VERSION ""

NS_ :

BS_:

BU_:
VAL_TABLE_ vtBridgeOperation 0 "Freewheeling" 1 "Forward" 2 "Reverse" 3 "Brake" 7 "Not available" ;
VAL_TABLE_ vtDigitalInput 0 "Low" 1 "High" 2 "Error" 3 "Not available" ;
VAL_TABLE_ vtOnOff 0 "Off" 1 "On" 2 "Error" 3 "Not available" ;
VAL_TABLE_ vtOutputDiag 0 "Unknown" 1 "OK" 2 "Open" 3 "Short to VBAT" 4 "Short to GND" 5 "Over-current" 6 "Over temperature" 14 "Error" 15 "Not available" ;
VAL_TABLE_ vtPwmFreq 0 "1 Hz" 1 "2 Hz" 2 "5 Hz" 3 "10 Hz" 4 "20 Hz" 5 "50 Hz" 6 "100 Hz" 7 "200 Hz" 8 "500 Hz" 9 "1 KHz" 10 "2 KHz" 11 "5 KHz" 12 "10 KHz" 13 "20 KHz" 14 "Error" 15 "Not available" ;
VAL_TABLE_ vtUInt16 65024 "Error" 65535 "Not available" ;
VAL_TABLE_ vtUInt32 -16777217 "Error" -1 "Not available" ;
VAL_TABLE_ vtUInt8 254 "Error" 255 "Not available" ;

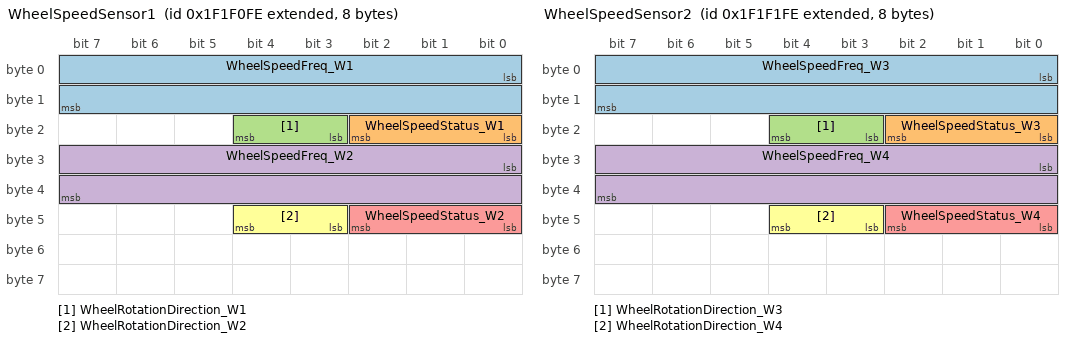
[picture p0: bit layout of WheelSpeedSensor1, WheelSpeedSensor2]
BO_ 2180116734 WheelSpeedSensor1: 8 Vector__XXX
 SG_ WheelSpeedFreq_W1 : 0|16@1+ (0.1,0) [0|6425.5] "Hz" Vector__XXX
 SG_ WheelSpeedStatus_W1 : 16|3@1+ (1,0) [0|7] "" Vector__XXX
 SG_ WheelRotationDirection_W1 : 19|2@1+ (1,0) [0|3] "" Vector__XXX
 SG_ WheelSpeedFreq_W2 : 24|16@1+ (0.1,0) [0|6425.5] "Hz" Vector__XXX
 SG_ WheelSpeedStatus_W2 : 40|3@1+ (1,0) [0|7] "" Vector__XXX
 SG_ WheelRotationDirection_W2 : 43|2@1+ (1,0) [0|3] "" Vector__XXX

BO_ 2180116990 WheelSpeedSensor2: 8 Vector__XXX
 SG_ WheelSpeedFreq_W3 : 0|16@1+ (0.1,0) [0|6425.5] "Hz" Vector__XXX
 SG_ WheelSpeedStatus_W3 : 16|3@1+ (1,0) [0|7] "" Vector__XXX
 SG_ WheelRotationDirection_W3 : 19|2@1+ (1,0) [0|3] "" Vector__XXX
 SG_ WheelSpeedFreq_W4 : 24|16@1+ (0.1,0) [0|6425.5] "Hz" Vector__XXX
 SG_ WheelSpeedStatus_W4 : 40|3@1+ (1,0) [0|7] "" Vector__XXX
 SG_ WheelRotationDirection_W4 : 43|2@1+ (1,0) [0|3] "" Vector__XXX

CM_ "Wheel Speed Sensor messages Version 0.0.1.0
$File: //system_software/components/lib/wheel_speed_sensor/0.36.0.0/dbc/WheelSpeedSensor.dbc $
$Change: 208863 $
$DateTime: 2023/11/10 13:11:00 $
$Revision: #1 $";
CM_ BO_ 2180116734 "Wheel Speed Sensor Iinformation 1";
CM_ SG_ 2180116734 WheelSpeedFreq_W1 "Wheel 1 speed sensor measured frequency";
CM_ SG_ 2180116734 WheelSpeedStatus_W1 "Wheel 1 speed sensor status";
CM_ SG_ 2180116734 WheelRotationDirection_W1 "Wheel 1 rotation direction";
CM_ SG_ 2180116734 WheelSpeedFreq_W2 "Wheel 2 speed sensor measured frequency";
CM_ SG_ 2180116734 WheelSpeedStatus_W2 "Wheel 2 speed sensor status";
CM_ SG_ 2180116734 WheelRotationDirection_W2 "Wheel 2 rotation direction";
CM_ BO_ 2180116990 "Wheel Speed Sensor Iinformation 2";
CM_ SG_ 2180116990 WheelSpeedFreq_W3 "Wheel 3 speed sensor measured frequency";
CM_ SG_ 2180116990 WheelSpeedStatus_W3 "Wheel 3 speed sensor status";
CM_ SG_ 2180116990 WheelRotationDirection_W3 "Wheel 3 rotation direction";
CM_ SG_ 2180116990 WheelSpeedFreq_W4 "Wheel 4 speed sensor measured frequency";
CM_ SG_ 2180116990 WheelSpeedStatus_W4 "Wheel 4 speed sensor status";
CM_ SG_ 2180116990 WheelRotationDirection_W4 "Wheel 4 rotation direction";
BA_DEF_  "BusType" STRING ;
BA_DEF_  "DBName" STRING ;
BA_DEF_  "DatabaseVersion" STRING ;
BA_DEF_ BO_  "GenMsgCycleTime" INT 0 3600000;
BA_DEF_ BO_  "GenMsgILSupport" ENUM  "No","Yes";
BA_DEF_ BO_  "GenMsgRequestable" INT 0 1;
BA_DEF_ BO_  "GenMsgSendType" ENUM  "cyclic","NotUsed","NotUsed","NotUsed","NotUsed","NotUsed","NotUsed","IfActive","noMsgSendType";
BA_DEF_ SG_  "GenSigEVName" STRING ;
BA_DEF_ SG_  "GenSigILSupport" ENUM  "No","Yes";
BA_DEF_ SG_  "GenSigSendType" ENUM  "Cyclic","OnWrite","OnWriteWithRepetition","OnChange","OnChangeWithRepetition","IfActive","IfActiveWithRepetition","NoSigSendType";
BA_DEF_ SG_  "GenSigStartValue" INT 0 2147483647;
BA_DEF_ BU_  "NmStationAddress" INT 0 255;
BA_DEF_  "ProtocolType" STRING ;
BA_DEF_  "SAE_J1939_21_SpecVersion" STRING ;
BA_DEF_  "SAE_J1939_71_SpecVersion" STRING ;
BA_DEF_  "SAE_J1939_73_SpecVersion" STRING ;
BA_DEF_  "SAE_J1939_75_SpecVersion" STRING ;
BA_DEF_  "SAE_J1939_81_SpecVersion" STRING ;
BA_DEF_  "SAE_J1939_DA_SpecVersion" STRING ;
BA_DEF_ SG_  "SigType" ENUM  "Default","Range","RangeSigned","ASCII","Discrete","Control","ReferencePGN","DTC","StringDelimiter","StringLength","StringLengthControl","MessageCounter","MessageChecksum";
BA_DEF_ BO_  "VFrameFormat" ENUM  "StandardCAN","ExtendedCAN","reserved","J1939PG";
BA_DEF_DEF_  "BusType" "";
BA_DEF_DEF_  "DBName" "";
BA_DEF_DEF_  "DatabaseVersion" "";
BA_DEF_DEF_  "GenMsgCycleTime" 0;
BA_DEF_DEF_  "GenMsgILSupport" "Yes";
BA_DEF_DEF_  "GenMsgRequestable" 1;
BA_DEF_DEF_  "GenMsgSendType" "noMsgSendType";
BA_DEF_DEF_  "GenSigEVName" "Env@Nodename_@Signame";
BA_DEF_DEF_  "GenSigILSupport" "Yes";
BA_DEF_DEF_  "GenSigSendType" "NoSigSendType";
BA_DEF_DEF_  "GenSigStartValue" 0;
BA_DEF_DEF_  "NmStationAddress" 254;
BA_DEF_DEF_  "ProtocolType" "";
BA_DEF_DEF_  "SAE_J1939_21_SpecVersion" "";
BA_DEF_DEF_  "SAE_J1939_71_SpecVersion" "";
BA_DEF_DEF_  "SAE_J1939_73_SpecVersion" "";
BA_DEF_DEF_  "SAE_J1939_75_SpecVersion" "";
BA_DEF_DEF_  "SAE_J1939_81_SpecVersion" "";
BA_DEF_DEF_  "SAE_J1939_DA_SpecVersion" "";
BA_DEF_DEF_  "SigType" "Default";
BA_DEF_DEF_  "VFrameFormat" "J1939PG";
BA_ "BusType" "CAN";
BA_ "DBName" "WheelSpeedSensor";
BA_ "DatabaseVersion" "8.5";
BA_ "ProtocolType" "J1939";
BA_ "SAE_J1939_21_SpecVersion" "2006-10";
BA_ "SAE_J1939_71_SpecVersion" "2012-10";
BA_ "SAE_J1939_73_SpecVersion" "2012-10";
BA_ "SAE_J1939_75_SpecVersion" "2012-05";
BA_ "SAE_J1939_81_SpecVersion" "2012-05";
BA_ "SAE_J1939_DA_SpecVersion" "2015-01";
BA_ "GenMsgCycleTime" BO_ 2180116734 10;
BA_ "GenMsgSendType" BO_ 2180116734 0;
BA_ "GenMsgCycleTime" BO_ 2180116990 10;
BA_ "GenMsgSendType" BO_ 2180116990 0;
BA_ "SigType" SG_ 2180116734 WheelSpeedFreq_W1 1;
BA_ "GenSigStartValue" SG_ 2180116734 WheelSpeedStatus_W1 7;
BA_ "GenSigStartValue" SG_ 2180116734 WheelRotationDirection_W1 3;
BA_ "SigType" SG_ 2180116734 WheelSpeedFreq_W2 1;
BA_ "GenSigStartValue" SG_ 2180116734 WheelSpeedStatus_W2 7;
BA_ "GenSigStartValue" SG_ 2180116734 WheelRotationDirection_W2 3;
BA_ "SigType" SG_ 2180116990 WheelSpeedFreq_W3 1;
BA_ "GenSigStartValue" SG_ 2180116990 WheelSpeedStatus_W3 7;
BA_ "GenSigStartValue" SG_ 2180116990 WheelRotationDirection_W3 3;
BA_ "SigType" SG_ 2180116990 WheelSpeedFreq_W4 1;
BA_ "GenSigStartValue" SG_ 2180116990 WheelSpeedStatus_W4 7;
BA_ "GenSigStartValue" SG_ 2180116990 WheelRotationDirection_W4 3;
VAL_ 2180116734 WheelSpeedStatus_W1 0 "OK" 1 "Airgap limit" 2 "Bad airgap" 6 "Error" 7 "Not Available" ;
VAL_ 2180116734 WheelRotationDirection_W1 0 "Right" 1 "Left" 2 "Stop" 3 "Not Available" ;
VAL_ 2180116734 WheelSpeedStatus_W2 0 "OK" 1 "Airgap limit" 2 "Bad airgap" 6 "Error" 7 "Not Available" ;
VAL_ 2180116734 WheelRotationDirection_W2 0 "Right" 1 "Left" 2 "Stop" 3 "Not Available" ;
VAL_ 2180116990 WheelSpeedStatus_W3 0 "OK" 1 "Airgap limit" 2 "Bad airgap" 6 "Error" 7 "Not Available" ;
VAL_ 2180116990 WheelRotationDirection_W3 0 "Right" 1 "Left" 2 "Stop" 3 "Not Available" ;
VAL_ 2180116990 WheelSpeedStatus_W4 0 "OK" 1 "Airgap limit" 2 "Bad airgap" 6 "Error" 7 "Not Available" ;
VAL_ 2180116990 WheelRotationDirection_W4 0 "Right" 1 "Left" 2 "Stop" 3 "Not Available" ;
